# R7FA6M3AH register map
Vendor: Renesas; Series: RA6; File version: 1.2
CPU: CM4 r0p1, little endian, MPU, FPU, VTOR, 4 interrupt priority bits
Registers are 32-bit, read-write, reset 0x0 unless marked. A register's access mark holds for its fields unless they carry their own. Offsets are from the block's base; [hi:lo] are bit positions; {n}, {i} and the like mark numbered series; 'fields as' and 'values as' point back to an identical list.

## SRAM — SRAM Control
Base 0x40002000
0x00 PARIOAD 8-bit — SRAM Parity Error Operation After Detection Register
  [0] OAD — Operation after Detection
    0=Non-maskable interrupt; 1=Reset
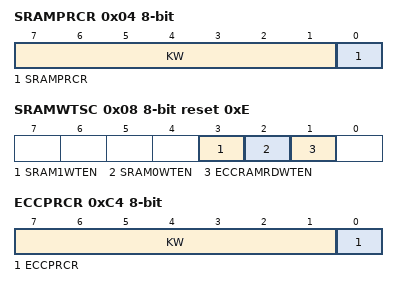
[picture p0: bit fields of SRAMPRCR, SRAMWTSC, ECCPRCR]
0x04 SRAMPRCR 8-bit — SRAM Protection Register
  [7:1] KW wo — Write Key Code
    120=Writing to the RAMPRCR bit is valid, when the KEY bits are written 1111000b; other=others (Writing to the RAMPRCR bit is invalid.)
  [0] SRAMPRCR — Register Write Control
    0=Disable writes to protected registers; 1=Enable writes to protected registers
0x08 SRAMWTSC 8-bit reset 0xE — RAM Wait State Control Register
  [3] SRAM1WTEN — SRAM1 Wait Enable
    0=Not add wait state in read access cycle to SRAM1; 1=Add wait state in read access cycle to SRAM1
  [2] SRAM0WTEN — SRAM0 Wait Enable
    0=Not add wait state in read access cycle to SRAM0; 1=Add wait state in read access cycle to SRAM0
  [1] ECCRAMRDWTEN — ECCRAM Read wait enable
    0=Not add wait state in read access cycle to SRAM0 (ECC area); 1=Add wait state in read access cycle to SRAM0 (ECC area)
0xC0 ECCMODE 8-bit — ECCRAM Operating Mode Control Register
  [1:0] ECCMOD — ECC Operating Mode Select
    0=Disable ECC function; 1=Setting prohibited; 2=Enable ECC function without error checking; 3=Enable ECC function with error checking
0xC1 ECC2STS 8-bit — ECCRAM 2-Bit Error Status Register
  [0] ECC2ERR write-0-clears read-modifies — ECC 2-Bit Error Status
    0=No 2-bit ECC error occurred; 1=2-bit ECC error occurred
0xC2 ECC1STSEN 8-bit — ECCRAM 1-Bit Error Information Update Enable Register
  [0] E1STSEN — ECC 1-Bit Error Information Update Enable
    0=Disables updating of the 1-bit ECC error information; 1=Enables updating of the 1-bit ECC error information
0xC3 ECC1STS 8-bit — ECCRAM 1-Bit Error Status Register
  [0] ECC1ERR write-0-clears read-modifies — ECC 1-Bit Error Status
    0=No 1-bit ECC error occurred; 1=1-bit ECC error occurred
0xC4 ECCPRCR 8-bit — ECCRAM Protection Register
  [7:1] KW wo — Write Key Code
    120=Writing to the ECCRAMPRCR bit is valid, when the KEY bits are written 1111000b; other=others (Writing to the ECCRAMPRCR bit is invalid.)
  [0] ECCPRCR — ECCRAMETST Register Write Control
    values as SRAMPRCR.SRAMPRCR
0xD4 ECCETST 8-bit — ECC Test Control Register
  [0] TSTBYP — ECC Bypass Select
    0=ECC bypass disabled; 1=ECC bypass enabled
0xD8 ECCOAD 8-bit — RAM ECC Error Operation After Detection Register
  [0] OAD — Operation after Detection
    0=Non maskable interrupt; 1=Internal reset

## GPT_ODC — PWM Delay Generation Circuit
Base 0x4007B000
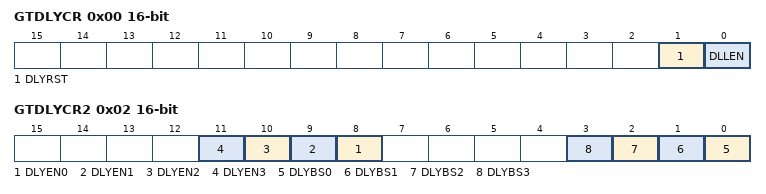
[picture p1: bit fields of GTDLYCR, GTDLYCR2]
0x00 GTDLYCR 16-bit — PWM Output Delay Control Register
  [1] DLYRST — PWM Delay Generation Circuit Reset
    0=Normal operation; 1=Reset
  [0] DLLEN — DLL Operation Enable
    0=Disable DLL operation; 1=Enable DLL operation
0x02 GTDLYCR2 16-bit — PWM Output Delay Control Register2
  [n+8] DLYEN{n} (n=0..3) — PWM Delay Generation Circuit enable for channel {n}
    0=Enable delay generation circuit of channel {n}; 1=Disable delay generation circuit of channel {n}
  [n] DLYBS{n} (n=0..3) — PWM Delay Generation Circuit bypass for channel {n}
    0=Bypass delay generation circuit of channel {n}; 1=Do not bypass delay generation circuit of channel {n}
{0x18+4i} GTDLYR{i}A (i=0..3) 16-bit (alternate view of GTDLYR{i}) — GTIOC{i}A Rising Output Delay Register
  [4:0] DLY — GTIOCnA Output Rising Edge Delay Setting
    0=No delay on rising edges; other=others (Delay of DLY/32 times the PCLKD period is applied.)
{0x1A+4i} GTDLYR{i}B (i=0..3) 16-bit (alternate view of GTDLYR{i}) — GTIOC{i}B Rising Output Delay Register
  [4:0] DLY — GTIOCnB Output Rising Edge Delay Setting
    values as GTDLYR0A.DLY
{0x28+4i} GTDLYF{i}A (i=0..3) 16-bit (alternate view of GTDLYF{i}) — GTIOC{i}A Falling Output Delay Register
  [4:0] DLY — GTIOCnA Output Falling Edge Delay Setting
    values as GTDLYR0A.DLY
{0x2A+4i} GTDLYF{i}B (i=0..3) 16-bit (alternate view of GTDLYF{i}) — GTIOC{i}B Falling Output Delay Register
  [4:0] DLY — GTIOCnB Output Falling Edge Delay Setting
    values as GTDLYR0A.DLY
